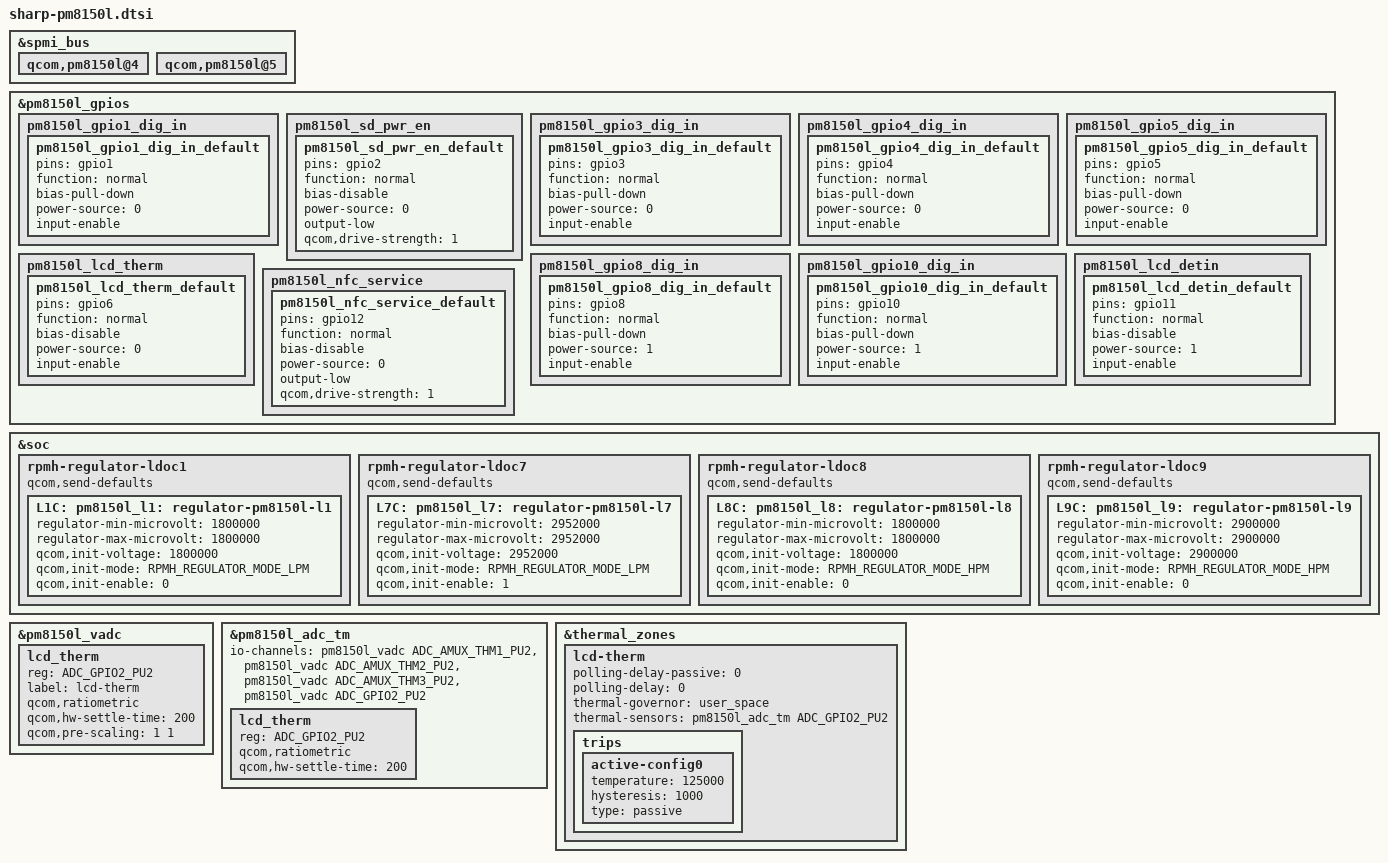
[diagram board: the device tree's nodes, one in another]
/*
 * Copyright (c) 2017-2018, The Linux Foundation. All rights reserved.
 *
 * This program is free software; you can redistribute it and/or modify
 * it under the terms of the GNU General Public License version 2 and
 * only version 2 as published by the Free Software Foundation.
 *
 * This program is distributed in the hope that it will be useful,
 * but WITHOUT ANY WARRANTY; without even the implied warranty of
 * MERCHANTABILITY or FITNESS FOR A PARTICULAR PURPOSE.  See the
 * GNU General Public License for more details.
 */

/*****************************************/
/*  pm8150l: qcom,pm8150l alias          */
/*****************************************/
&spmi_bus {
	qcom,pm8150l@4 {
	};

	qcom,pm8150l@5 {
	};
};

/*****************************************/
/*  pm8150l-gpios: qpnp-pin               */
/*****************************************/
&pm8150l_gpios {
	pm8150l_gpio1_dig_in{
		/* I/PD/L */	/* - */
		pm8150l_gpio1_dig_in_default: pm8150l_gpio1_dig_in_default{
			pins = "gpio1";			/* GPIO 1 */
			function = "normal";		/* Normal Input */
			bias-pull-down;			/* Pull Down */
			power-source = <0>;		/* VIN0 */
			input-enable;			/* Digital Input */
		};
	};

	pm8150l_sd_pwr_en{
		/* O/NP/0 */	/* - */
		pm8150l_sd_pwr_en_default: pm8150l_sd_pwr_en_default{
			pins = "gpio2";			/* GPIO 2 */
			function = "normal";		/* Normal Output */
			bias-disable;			/* No Pull */
			power-source = <0>;		/* VIN0 */
			output-low;			/* Output Low */
			qcom,drive-strength = <1>;	/* Low strength */
		};
	};

	pm8150l_gpio3_dig_in{
		/* I/PD/L */	/* - */
		pm8150l_gpio3_dig_in_default: pm8150l_gpio3_dig_in_default{
			pins = "gpio3";			/* GPIO 3 */
			function = "normal";		/* Normal Input */
			bias-pull-down;			/* Pull Down */
			power-source = <0>;		/* VIN0 */
			input-enable;			/* Digital Input */
		};
	};

	pm8150l_gpio4_dig_in{
		/* I/PD/L */	/* - */
		pm8150l_gpio4_dig_in_default: pm8150l_gpio4_dig_in_default{
			pins = "gpio4";			/* GPIO 4 */
			function = "normal";		/* Normal Input */
			bias-pull-down;			/* Pull Down */
			power-source = <0>;		/* VIN0 */
			input-enable;			/* Digital Input */
		};
	};

	pm8150l_gpio5_dig_in{
		/* I/PD/L */	/* - */
		pm8150l_gpio5_dig_in_default: pm8150l_gpio5_dig_in_default{
			pins = "gpio5";			/* GPIO 5 */
			function = "normal";		/* Normal Input */
			bias-pull-down;			/* Pull Down */
			power-source = <0>;		/* VIN0 */
			input-enable;			/* Digital Input */
		};
	};

	pm8150l_lcd_therm{
		/* I/NP/L */	/* LCD_THERM */
		pm8150l_lcd_therm_default: pm8150l_lcd_therm_default{
			pins = "gpio6";			/* GPIO 6 */
			function = "normal";	/* Normal Input */
			bias-disable;			/* No Pull */
			power-source = <0>;		/* VIN0 */
			input-enable;			/* Digital Input */
		};
	};

	pm8150l_gpio8_dig_in{
		/* I/PD/L */	/* - */
		pm8150l_gpio8_dig_in_default: pm8150l_gpio8_dig_in_default{
			pins = "gpio8";			/* GPIO 8 */
			function = "normal";		/* Normal Input */
			bias-pull-down;			/* Pull Down */
			power-source = <1>;		/* VIN1 */
			input-enable;			/* Digital Input */
		};
	};

	pm8150l_gpio10_dig_in{
		/* I/PD/L */	/* - */
		pm8150l_gpio10_dig_in_default: pm8150l_gpio10_dig_in_default{
			pins = "gpio10";		/* GPIO 10 */
			function = "normal";		/* Normal Input */
			bias-pull-down;			/* Pull Down */
			power-source = <1>;		/* VIN1 */
			input-enable;			/* Digital Input */
		};
	};

	pm8150l_lcd_detin{
		/* I/NP/L */	/* - */
		pm8150l_lcd_detin_default: pm8150l_lcd_detin_default{
			pins = "gpio11";		/* GPIO 11 */
			function = "normal";		/* Normal Input */
			bias-disable;            /* No Pull */
			power-source = <1>;		/* VIN1 */
			input-enable;            /* Digital Input */
		};
	};

	pm8150l_nfc_service{
		/* O/NP/0 */	/* - */
		pm8150l_nfc_service_default: pm8150l_nfc_service_default{
			pins = "gpio12";		/* GPIO 12 */
			function = "normal";		/* Normal Output */
			bias-disable;			/* No Pull */
			power-source = <0>;		/* VIN0 */
			output-low;			/* Output Low */
			qcom,drive-strength = <1>;	/* Low strength */
		};
	};
};

/*****************************************/
/*  pm8150l: rpm-regulator                */
/*****************************************/
&soc{
	rpmh-regulator-ldoc1 {
		qcom,send-defaults;
		L1C: pm8150l_l1: regulator-pm8150l-l1 {
			regulator-min-microvolt = <1800000>;
			regulator-max-microvolt = <1800000>;
			qcom,init-voltage = <1800000>;
			qcom,init-mode = <RPMH_REGULATOR_MODE_LPM>;
			qcom,init-enable = <0>;
		};
	};

	rpmh-regulator-ldoc7 {
		qcom,send-defaults;
		L7C: pm8150l_l7: regulator-pm8150l-l7 {
			regulator-min-microvolt = <2952000>;
			regulator-max-microvolt = <2952000>;
			qcom,init-voltage = <2952000>;
			qcom,init-mode = <RPMH_REGULATOR_MODE_LPM>;
			qcom,init-enable = <1>;
		};
	};

	rpmh-regulator-ldoc8 {
		qcom,send-defaults;
		L8C: pm8150l_l8: regulator-pm8150l-l8 {
			regulator-min-microvolt = <1800000>;
			regulator-max-microvolt = <1800000>;
			qcom,init-voltage = <1800000>;
			qcom,init-mode = <RPMH_REGULATOR_MODE_HPM>;
			qcom,init-enable = <0>;
		};
	};

	rpmh-regulator-ldoc9 {
		qcom,send-defaults;
		L9C: pm8150l_l9: regulator-pm8150l-l9 {
			regulator-min-microvolt = <2900000>;
			regulator-max-microvolt = <2900000>;
			qcom,init-voltage = <2900000>;
			qcom,init-mode = <RPMH_REGULATOR_MODE_HPM>;
			qcom,init-enable = <0>;
		};
	};
};

/*****************************************/
/*  pm8150l_vadc:spmi-adc5               */
/*****************************************/
&pm8150l_vadc {
	lcd_therm {
		reg = <ADC_GPIO2_PU2>;
		label = "lcd-therm";
		qcom,ratiometric;
		qcom,hw-settle-time = <200>;
		qcom,pre-scaling = <1 1>;
	};
};

/*****************************************/
/*  pm8150l_adc_tm:adc-tm5               */
/*****************************************/
&pm8150l_adc_tm {
	io-channels = <&pm8150l_vadc ADC_AMUX_THM1_PU2>,
			<&pm8150l_vadc ADC_AMUX_THM2_PU2>,
			<&pm8150l_vadc ADC_AMUX_THM3_PU2>,
			<&pm8150l_vadc ADC_GPIO2_PU2>;

	lcd_therm {
		reg = <ADC_GPIO2_PU2>;
		qcom,ratiometric;
		qcom,hw-settle-time = <200>;
	};
};

/*****************************************/
/*  thermal_zones                        */
/*****************************************/
&thermal_zones {
	lcd-therm {
		polling-delay-passive = <0>;
		polling-delay = <0>;
		thermal-governor = "user_space";
		thermal-sensors = <&pm8150l_adc_tm ADC_GPIO2_PU2>;
		trips {
			active-config0 {
				temperature = <125000>;
				hysteresis = <1000>;
				type = "passive";
			};
		};
	};
};
